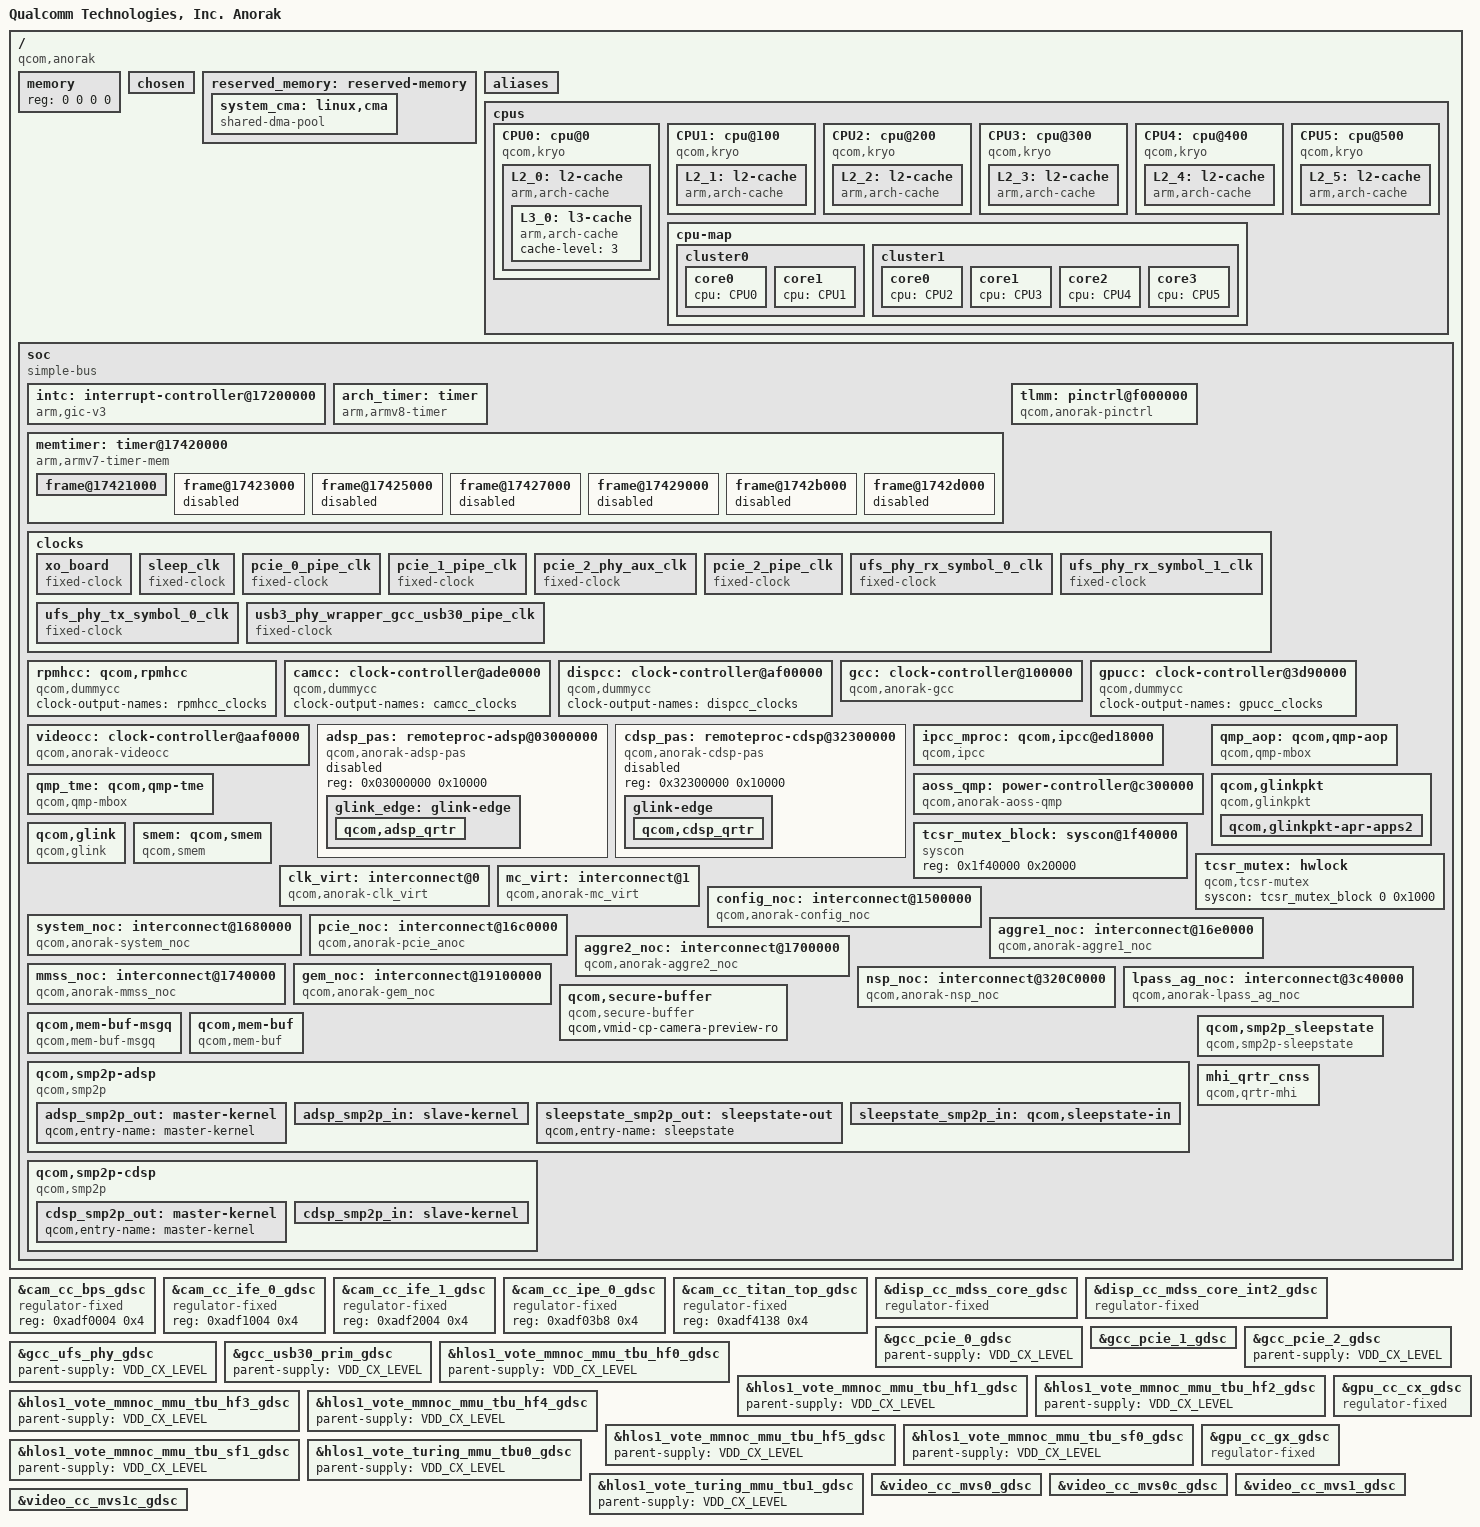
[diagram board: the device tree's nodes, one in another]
#include <dt-bindings/clock/qcom,rpmh.h>
#include <dt-bindings/clock/qcom,camcc-anorak.h>
#include <dt-bindings/clock/qcom,dispcc-anorak.h>
#include <dt-bindings/clock/qcom,gcc-anorak.h>
#include <dt-bindings/clock/qcom,gpucc-anorak.h>
#include <dt-bindings/clock/qcom,videocc-anorak.h>
#include <dt-bindings/interrupt-controller/arm-gic.h>
#include <dt-bindings/interconnect/qcom,icc.h>
#include <dt-bindings/interconnect/qcom,anorak.h>
#include <dt-bindings/soc/qcom,ipcc.h>

/ {
	model = "Qualcomm Technologies, Inc. Anorak";
	compatible = "qcom,anorak";
	qcom,msm-id = <549 0x10000>;
	interrupt-parent = <&intc>;

	#address-cells = <2>;
	#size-cells = <2>;
	memory { device_type = "memory"; reg = <0 0 0 0>; };


	chosen: chosen {
		bootargs = "console=ttyMSM0,115200n8 loglevel=8 log_buf_len=256K kernel.panic_on_rcu_stall=1 loop.max_part=7 service_locator.enable=1 msm_rtb.filter=0x237 allow_mismatched_32bit_el0 kasan=off rcupdate.rcu_expedited=1 rcu_nocbs=0-5 ftrace_dump_on_oops pstore.compress=none kpti=off swiotlb=noforce cgroup.memory=nokmem,nosocket allow_file_spec_access";

	};

	reserved_memory: reserved-memory { };

	aliases { };

	cpus {
		#address-cells = <2>;
		#size-cells = <0>;

		CPU0: cpu@0 {
			device_type = "cpu";
			compatible = "qcom,kryo";
			reg = <0x0 0x0>;
			enable-method = "spin-table";
			cpu-release-addr = <0x0 0x90000000>;
			next-level-cache = <&L2_0>;
			L2_0: l2-cache {
			      compatible = "arm,arch-cache";
			      cache-level = <2>;
			      next-level-cache = <&L3_0>;

				L3_0: l3-cache {
					compatible = "arm,arch-cache";
					cache-level = <3>;
				};
			};
		};

		CPU1: cpu@100 {
			device_type = "cpu";
			compatible = "qcom,kryo";
			reg = <0x0 0x100>;
			enable-method = "spin-table";
			cpu-release-addr = <0x0 0x90000000>;
			next-level-cache = <&L2_1>;
			L2_1: l2-cache {
			      compatible = "arm,arch-cache";
			      cache-level = <2>;
			      next-level-cache = <&L3_0>;
			};

		};

		CPU2: cpu@200 {
			device_type = "cpu";
			compatible = "qcom,kryo";
			reg = <0x0 0x200>;
			enable-method = "spin-table";
			cpu-release-addr = <0x0 0x90000000>;
			next-level-cache = <&L2_2>;
			L2_2: l2-cache {
			      compatible = "arm,arch-cache";
			      cache-level = <2>;
			      next-level-cache = <&L3_0>;
			};
		};

		CPU3: cpu@300 {
			device_type = "cpu";
			compatible = "qcom,kryo";
			reg = <0x0 0x300>;
			enable-method = "spin-table";
			cpu-release-addr = <0x0 0x90000000>;
			next-level-cache = <&L2_3>;
			L2_3: l2-cache {
			      compatible = "arm,arch-cache";
			      cache-level = <2>;
			      next-level-cache = <&L3_0>;
			};

		};

		CPU4: cpu@400 {
			device_type = "cpu";
			compatible = "qcom,kryo";
			reg = <0x0 0x400>;
			enable-method = "spin-table";
			cpu-release-addr = <0x0 0x90000000>;
			next-level-cache = <&L2_4>;
			L2_4: l2-cache {
				compatible = "arm,arch-cache";
				cache-level = <2>;
				next-level-cache = <&L3_0>;
			};
		};

		CPU5: cpu@500 {
			device_type = "cpu";
			compatible = "qcom,kryo";
			reg = <0x0 0x500>;
			enable-method = "spin-table";
			cpu-release-addr = <0x0 0x90000000>;
			next-level-cache = <&L2_5>;
			L2_5: l2-cache {
				compatible = "arm,arch-cache";
				cache-level = <2>;
				next-level-cache = <&L3_0>;
			};
		};

		cpu-map {
			cluster0 {
				core0 {
					cpu = <&CPU0>;
				};

				core1 {
					cpu = <&CPU1>;
				};
			};

			cluster1 {
				core0 {
					cpu = <&CPU2>;
				};

				core1 {
					cpu = <&CPU3>;
				};

				core2 {
					cpu = <&CPU4>;
				};

				core3 {
					cpu = <&CPU5>;
				};
			};
		};
	};

	soc: soc { };
};

#include "anorak-reserved-memory.dtsi"

&reserved_memory {
	#address-cells = <2>;
	#size-cells = <2>;
	ranges;

	/* global autoconfigured region for contiguous allocations */
	system_cma: linux,cma {
		compatible = "shared-dma-pool";
		alloc-ranges = <0x0 0x00000000 0x0 0xffffffff>;
		reusable;
		alignment = <0x0 0x400000>;
		size = <0x0 0x2000000>;
		linux,cma-default;
	};
};

&soc {
	#address-cells = <1>;
	#size-cells = <1>;
	ranges = <0 0 0 0xffffffff>;
	compatible = "simple-bus";

	intc: interrupt-controller@17200000 {
		compatible = "arm,gic-v3";
		#interrupt-cells = <3>;
		interrupt-controller;
		#redistributor-regions = <1>;
		redistributor-stride = <0x0 0x20000>;
		reg = <0x17200000 0x10000>,	/* GICD */
		      <0x17260000 0x100000>;	/* GICR * 8 */
		interrupts = <GIC_PPI 9 IRQ_TYPE_LEVEL_LOW>;
	};

	arch_timer: timer {
		compatible = "arm,armv8-timer";
		interrupts = <GIC_PPI 13 (GIC_CPU_MASK_SIMPLE(8) | IRQ_TYPE_LEVEL_LOW)>,
			     <GIC_PPI 14 (GIC_CPU_MASK_SIMPLE(8) | IRQ_TYPE_LEVEL_LOW)>,
			     <GIC_PPI 11 (GIC_CPU_MASK_SIMPLE(8) | IRQ_TYPE_LEVEL_LOW)>,
			     <GIC_PPI 12 (GIC_CPU_MASK_SIMPLE(8) | IRQ_TYPE_LEVEL_LOW)>;
		clock-frequency = <19200000>;
	};

	memtimer: timer@17420000 {
		#address-cells = <1>;
		#size-cells = <1>;
		ranges;
		compatible = "arm,armv7-timer-mem";
		reg = <0x17420000 0x1000>;
		clock-frequency = <19200000>;

		frame@17421000 {
			frame-number = <0>;
			interrupts = <GIC_SPI 8 IRQ_TYPE_LEVEL_HIGH>,
				     <GIC_SPI 6 IRQ_TYPE_LEVEL_HIGH>;
			reg = <0x17421000 0x1000>,
			      <0x17422000 0x1000>;
		};

		frame@17423000 {
			frame-number = <1>;
			interrupts = <GIC_SPI 9 IRQ_TYPE_LEVEL_HIGH>;
			reg = <0x17423000 0x1000>;
			status = "disabled";
		};

		frame@17425000 {
			frame-number = <2>;
			interrupts = <GIC_SPI 10 IRQ_TYPE_LEVEL_HIGH>;
			reg = <0x17425000 0x1000>;
			status = "disabled";
		};

		frame@17427000 {
			frame-number = <3>;
			interrupts = <GIC_SPI 11 IRQ_TYPE_LEVEL_HIGH>;
			reg = <0x17427000 0x1000>;
			status = "disabled";
		};

		frame@17429000 {
			frame-number = <4>;
			interrupts = <GIC_SPI 12 IRQ_TYPE_LEVEL_HIGH>;
			reg = <0x17429000 0x1000>;
			status = "disabled";
		};

		frame@1742b000 {
			frame-number = <5>;
			interrupts = <GIC_SPI 13 IRQ_TYPE_LEVEL_HIGH>;
			reg = <0x1742b000 0x1000>;
			status = "disabled";
		};

		frame@1742d000 {
			frame-number = <6>;
			interrupts = <GIC_SPI 14 IRQ_TYPE_LEVEL_HIGH>;
			reg = <0x1742d000 0x1000>;
			status = "disabled";
		};
	};

	tlmm: pinctrl@f000000 {
		compatible = "qcom,anorak-pinctrl";
		reg = <0xf000000 0x1000000>;
		interrupts = <GIC_SPI 208 IRQ_TYPE_LEVEL_HIGH>;
		gpio-controller;
		#gpio-cells = <2>;
		interrupt-controller;
		#interrupt-cells = <2>;
	};

	clocks {
		xo_board: xo_board {
			compatible = "fixed-clock";
			clock-frequency = <76800000>;
			clock-output-names = "xo_board";
			#clock-cells = <0>;
		};

		sleep_clk: sleep_clk {
			compatible = "fixed-clock";
			clock-frequency = <32000>;
			clock-output-names = "sleep_clk";
			#clock-cells = <0>;
		};

		pcie_0_pipe_clk: pcie_0_pipe_clk {
			compatible = "fixed-clock";
			clock-frequency = <1000>;
			clock-output-names = "pcie_0_pipe_clk";
			#clock-cells = <0>;
		};

		pcie_1_pipe_clk: pcie_1_pipe_clk {
			compatible = "fixed-clock";
			clock-frequency = <1000>;
			clock-output-names = "pcie_1_pipe_clk";
			#clock-cells = <0>;
		};

		pcie_2_phy_aux_clk: pcie_2_phy_aux_clk {
			compatible = "fixed-clock";
			clock-frequency = <1000>;
			clock-output-names = "pcie_2_phy_aux_clk";
			#clock-cells = <0>;
		};

		pcie_2_pipe_clk: pcie_2_pipe_clk {
			compatible = "fixed-clock";
			clock-frequency = <1000>;
			clock-output-names = "pcie_2_pipe_clk";
			#clock-cells = <0>;
		};

		ufs_phy_rx_symbol_0_clk: ufs_phy_rx_symbol_0_clk {
			compatible = "fixed-clock";
			clock-frequency = <1000>;
			clock-output-names = "ufs_phy_rx_symbol_0_clk";
			#clock-cells = <0>;
		};

		ufs_phy_rx_symbol_1_clk: ufs_phy_rx_symbol_1_clk {
			compatible = "fixed-clock";
			clock-frequency = <1000>;
			clock-output-names = "ufs_phy_rx_symbol_1_clk";
			#clock-cells = <0>;
		};

		ufs_phy_tx_symbol_0_clk: ufs_phy_tx_symbol_0_clk {
			compatible = "fixed-clock";
			clock-frequency = <1000>;
			clock-output-names = "ufs_phy_tx_symbol_0_clk";
			#clock-cells = <0>;
		};

		usb3_phy_wrapper_gcc_usb30_pipe_clk: usb3_phy_wrapper_gcc_usb30_pipe_clk {
			compatible = "fixed-clock";
			clock-frequency = <1000>;
			clock-output-names = "usb3_phy_wrapper_gcc_usb30_pipe_clk";
			#clock-cells = <0>;
		};
	};

	rpmhcc: qcom,rpmhcc {
		compatible = "qcom,dummycc";
		clock-output-names = "rpmhcc_clocks";
		#clock-cells = <1>;
		#reset-cells = <1>;
	};

	camcc: clock-controller@ade0000 {
		compatible = "qcom,dummycc";
		clock-output-names = "camcc_clocks";
		#clock-cells = <1>;
		#reset-cells = <1>;
	};

	dispcc: clock-controller@af00000 {
		compatible = "qcom,dummycc";
		clock-output-names = "dispcc_clocks";
		#clock-cells = <1>;
		#reset-cells = <1>;
	};

	gcc: clock-controller@100000 {
		compatible = "qcom,anorak-gcc", "syscon";
		reg = <0x100000 0x1f4200>;
		reg-name = "cc_base";
		vdd_cx-supply = <&VDD_CX_LEVEL>;
		vdd_mxa-supply = <&VDD_MXA_LEVEL>;
		clocks = <&rpmhcc RPMH_CXO_CLK>, <&sleep_clk>,
			<&pcie_0_pipe_clk>, <&pcie_1_pipe_clk>,
			<&pcie_2_phy_aux_clk>, <&pcie_2_pipe_clk>,
			<&ufs_phy_rx_symbol_0_clk>, <&ufs_phy_rx_symbol_1_clk>,
			<&ufs_phy_tx_symbol_0_clk>, <&usb3_phy_wrapper_gcc_usb30_pipe_clk>;
		clock-names = "bi_tcxo", "sleep_clk",
			"pcie_0_pipe_clk", "pcie_1_pipe_clk",
			"pcie_2_phy_aux_clk", "pcie_2_pipe_clk",
			"ufs_phy_rx_symbol_0_clk", "ufs_phy_rx_symbol_1_clk",
			"ufs_phy_tx_symbol_0_clk", "usb3_phy_wrapper_gcc_usb30_pipe_clk";
		#clock-cells = <1>;
		#reset-cells = <1>;
	};

	gpucc: clock-controller@3d90000 {
		compatible = "qcom,dummycc";
		clock-output-names = "gpucc_clocks";
		#clock-cells = <1>;
		#reset-cells = <1>;
	};

	videocc: clock-controller@aaf0000 {
		compatible = "qcom,anorak-videocc", "syscon";
		reg = <0xaaf0000 0x10000>;
		reg-name = "cc_base";
		vdd_mm-supply = <&VDD_MM_LEVEL>;
		vdd_mxc-supply = <&VDD_MXC_LEVEL>;
		clocks = <&rpmhcc RPMH_CXO_CLK>,
			<&sleep_clk>,
			<&gcc GCC_VIDEO_AHB_CLK>;
		clock-names = "bi_tcxo", "sleep_clk",
			"iface";
		#clock-cells = <1>;
		#reset-cells = <1>;
	};

	adsp_pas: remoteproc-adsp@03000000 {
		compatible = "qcom,anorak-adsp-pas";
		reg = <0x03000000 0x10000>;
		status = "disabled";
		glink_edge: glink-edge {
			qcom,remote-pid = <2>;
			transport = "smem";
			mboxes = <&ipcc_mproc IPCC_CLIENT_LPASS
			IPCC_MPROC_SIGNAL_GLINK_QMP>;
			mbox-names = "adsp_smem";
			interrupt-parent = <&ipcc_mproc>;
			interrupts = <IPCC_CLIENT_LPASS
					IPCC_MPROC_SIGNAL_GLINK_QMP
					IRQ_TYPE_EDGE_RISING>;

			label = "adsp";
			qcom,glink-label = "lpass";

			qcom,adsp_qrtr {
				qcom,glink-channels = "IPCRTR";
				qcom,intents = <0x800  5
						0x2000 3
						0x4400 2>;
			};
		};
	};

	cdsp_pas: remoteproc-cdsp@32300000 {
		compatible = "qcom,anorak-cdsp-pas";
		reg = <0x32300000 0x10000>;
		status = "disabled";
		glink-edge {
			qcom,remote-pid = <5>;
			transport = "smem";
			mboxes = <&ipcc_mproc IPCC_CLIENT_CDSP
					  IPCC_MPROC_SIGNAL_GLINK_QMP>;
			mbox-names = "cdsp_smem";
			interrupt-parent = <&ipcc_mproc>;
			interrupts = <IPCC_CLIENT_CDSP
				  IPCC_MPROC_SIGNAL_GLINK_QMP
				  IRQ_TYPE_EDGE_RISING>;

			label = "cdsp";
			qcom,glink-label = "cdsp";

			qcom,cdsp_qrtr {
				qcom,glink-channels = "IPCRTR";
				qcom,intents = <0x800  5
						0x2000 3
						0x4400 2>;
			};
		};
	};

	ipcc_mproc: qcom,ipcc@ed18000 {
		compatible = "qcom,ipcc";
		reg = <0x408000 0x1000>;
		interrupts = <GIC_SPI 229 IRQ_TYPE_LEVEL_HIGH>;
		interrupt-controller;
		#interrupt-cells = <3>;
		#mbox-cells = <2>;
	};

	aoss_qmp: power-controller@c300000 {
		compatible = "qcom,anorak-aoss-qmp";
		reg = <0xc300000 0x400>;
		interrupt-parent = <&ipcc_mproc>;
		interrupts = <IPCC_CLIENT_AOP
				IPCC_MPROC_SIGNAL_GLINK_QMP
				IRQ_TYPE_EDGE_RISING>;
		mboxes = <&ipcc_mproc IPCC_CLIENT_AOP
		IPCC_MPROC_SIGNAL_GLINK_QMP>;

		#power-domain-cells = <1>;
		#clock-cells = <0>;
	};

	qmp_aop: qcom,qmp-aop {
		compatible = "qcom,qmp-mbox";
		qcom,qmp = <&aoss_qmp>;
		label = "aop";
		#mbox-cells = <1>;
	};

	qmp_tme: qcom,qmp-tme {
		compatible = "qcom,qmp-mbox";
		qcom,remote-pid = <14>;
		mboxes = <&ipcc_mproc IPCC_CLIENT_TME
				IPCC_MPROC_SIGNAL_GLINK_QMP>;
		mbox-names = "tme_qmp";
		interrupt-parent = <&ipcc_mproc>;
		interrupts = <IPCC_CLIENT_TME
				IPCC_MPROC_SIGNAL_GLINK_QMP
				IRQ_TYPE_EDGE_RISING>;

		label = "tme";
		qcom,early-boot;
		priority = <0>;
		mbox-desc-offset = <0x0>;
		#mbox-cells = <1>;
	};

	qcom,glinkpkt {
		compatible = "qcom,glinkpkt";

		qcom,glinkpkt-apr-apps2 {
			qcom,glinkpkt-edge = "adsp";
			qcom,glinkpkt-ch-name = "apr_apps2";
			qcom,glinkpkt-dev-name = "apr_apps2";
		};
	};

	qcom,glink {
		compatible = "qcom,glink";
	};

	tcsr_mutex_block: syscon@1f40000 {
		compatible = "syscon";
		reg = <0x1f40000 0x20000>;
	};

	tcsr_mutex: hwlock {
		compatible = "qcom,tcsr-mutex";
		syscon = <&tcsr_mutex_block 0 0x1000>;
		#hwlock-cells = <1>;
		};

	smem: qcom,smem {
		compatible = "qcom,smem";
		memory-region = <&smem_mem>;
		hwlocks = <&tcsr_mutex 3>;
	};

	clk_virt: interconnect@0 {
		compatible = "qcom,anorak-clk_virt";
		#interconnect-cells = <1>;
	};

	mc_virt: interconnect@1 {
		compatible = "qcom,anorak-mc_virt";
		#interconnect-cells = <1>;
	};

	config_noc: interconnect@1500000 {
		compatible = "qcom,anorak-config_noc";
		#interconnect-cells = <1>;
	};

	system_noc: interconnect@1680000 {
		compatible = "qcom,anorak-system_noc";
		#interconnect-cells = <1>;
	};

	pcie_noc: interconnect@16c0000 {
		compatible = "qcom,anorak-pcie_anoc";
		#interconnect-cells = <1>;
	};

	aggre1_noc: interconnect@16e0000 {
		compatible = "qcom,anorak-aggre1_noc";
		#interconnect-cells = <1>;
	};

	aggre2_noc: interconnect@1700000 {
		compatible = "qcom,anorak-aggre2_noc";
		#interconnect-cells = <1>;
	};

	mmss_noc: interconnect@1740000 {
		compatible = "qcom,anorak-mmss_noc";
		#interconnect-cells = <1>;
	};

	gem_noc: interconnect@19100000 {
		compatible = "qcom,anorak-gem_noc";
		#interconnect-cells = <1>;
	};

	nsp_noc: interconnect@320C0000 {
		compatible = "qcom,anorak-nsp_noc";
		#interconnect-cells = <1>;
	};

	lpass_ag_noc: interconnect@3c40000 {
		compatible = "qcom,anorak-lpass_ag_noc";
		#interconnect-cells = <1>;
	};

	qcom,secure-buffer {
		compatible = "qcom,secure-buffer";
		qcom,vmid-cp-camera-preview-ro;
	};

	qcom,mem-buf-msgq {
		compatible = "qcom,mem-buf-msgq";
	};

	qcom,mem-buf {
		compatible = "qcom,mem-buf";
		qcom,mem-buf-capabilities = "supplier";
		qcom,vmid = <3>;
	};

	qcom,smp2p-adsp {
		compatible = "qcom,smp2p";
		qcom,smem = <443>, <429>;
		interrupt-parent = <&ipcc_mproc>;
		interrupts = <IPCC_CLIENT_LPASS IPCC_MPROC_SIGNAL_SMP2P
			      IRQ_TYPE_EDGE_RISING>;
		mboxes = <&ipcc_mproc IPCC_CLIENT_LPASS
			  IPCC_MPROC_SIGNAL_SMP2P>;
		qcom,local-pid = <0>;
		qcom,remote-pid = <2>;

		adsp_smp2p_out: master-kernel {
			qcom,entry-name = "master-kernel";
			#qcom,smem-state-cells = <1>;
		};

		adsp_smp2p_in: slave-kernel {
			qcom,entry-name = "slave-kernel";
			interrupt-controller;
			#interrupt-cells = <2>;
		};

		sleepstate_smp2p_out: sleepstate-out {
			qcom,entry-name = "sleepstate";
			#qcom,smem-state-cells = <1>;
		};

		sleepstate_smp2p_in: qcom,sleepstate-in {
			qcom,entry-name = "sleepstate_see";
			interrupt-controller;
			#interrupt-cells = <2>;
		};
	};

	qcom,smp2p-cdsp {
		compatible = "qcom,smp2p";
		qcom,smem = <94>, <432>;
		interrupt-parent = <&ipcc_mproc>;
		interrupts = <IPCC_CLIENT_CDSP IPCC_MPROC_SIGNAL_SMP2P
			      IRQ_TYPE_EDGE_RISING>;
		mboxes = <&ipcc_mproc IPCC_CLIENT_CDSP IPCC_MPROC_SIGNAL_SMP2P>;
		qcom,local-pid = <0>;
		qcom,remote-pid = <5>;

		cdsp_smp2p_out: master-kernel {
			qcom,entry-name = "master-kernel";
			#qcom,smem-state-cells = <1>;
		};

		cdsp_smp2p_in: slave-kernel {
			qcom,entry-name = "slave-kernel";
			interrupt-controller;
			#interrupt-cells = <2>;
		};
	};

	qcom,smp2p_sleepstate {
		compatible = "qcom,smp2p-sleepstate";
		qcom,smem-states = <&sleepstate_smp2p_out 0>;
		interrupt-parent = <&sleepstate_smp2p_in>;
		interrupts = <0 0>;
		interrupt-names = "smp2p-sleepstate-in";
	};

	mhi_qrtr_cnss {
		compatible = "qcom,qrtr-mhi";
		qcom,dev-id = <0x1103>;
		qcom,net-id = <0>;
		qcom,low-latency;
	};
};

#include "diwali-gdsc.dtsi"

&cam_cc_bps_gdsc {
	compatible = "regulator-fixed";
	reg = <0xadf0004 0x4>;
	status = "ok";
};

&cam_cc_ife_0_gdsc {
	compatible = "regulator-fixed";
	reg = <0xadf1004 0x4>;
	status = "ok";
};

&cam_cc_ife_1_gdsc {
	compatible = "regulator-fixed";
	reg = <0xadf2004 0x4>;
	status = "ok";
};

&cam_cc_ipe_0_gdsc {
	compatible = "regulator-fixed";
	reg = <0xadf03b8 0x4>;
	status = "ok";
};

&cam_cc_titan_top_gdsc {
	compatible = "regulator-fixed";
	reg = <0xadf4138 0x4>;
	status = "ok";
};

&disp_cc_mdss_core_gdsc {
	compatible = "regulator-fixed";
	status = "ok";
};

&disp_cc_mdss_core_int2_gdsc {
	compatible = "regulator-fixed";
	status = "ok";
};

&gcc_pcie_0_gdsc {
	parent-supply = <&VDD_CX_LEVEL>;
	status="ok";
};

&gcc_pcie_1_gdsc {
	parent-supply = <&VDD_CX_LEVEL>;
	reg = <0x1ad004 0x4>;
	qcom,support-hw-trigger;
	status="ok";
};

&gcc_pcie_2_gdsc {
	parent-supply = <&VDD_CX_LEVEL>;
	status="ok";
};

&gcc_ufs_phy_gdsc {
	parent-supply = <&VDD_CX_LEVEL>;
	status = "ok";
};

&gcc_usb30_prim_gdsc {
	parent-supply = <&VDD_CX_LEVEL>;
	status = "ok";
};

&hlos1_vote_mmnoc_mmu_tbu_hf0_gdsc {
	parent-supply = <&VDD_CX_LEVEL>;
	status = "ok";
};

&hlos1_vote_mmnoc_mmu_tbu_hf1_gdsc {
	parent-supply = <&VDD_CX_LEVEL>;
	status = "ok";
};

&hlos1_vote_mmnoc_mmu_tbu_hf2_gdsc {
	parent-supply = <&VDD_CX_LEVEL>;
	status = "ok";
};

&hlos1_vote_mmnoc_mmu_tbu_hf3_gdsc {
	parent-supply = <&VDD_CX_LEVEL>;
	status = "ok";
};

&hlos1_vote_mmnoc_mmu_tbu_hf4_gdsc {
	parent-supply = <&VDD_CX_LEVEL>;
	status = "ok";
};

&hlos1_vote_mmnoc_mmu_tbu_hf5_gdsc {
	parent-supply = <&VDD_CX_LEVEL>;
	status = "ok";
};

&hlos1_vote_mmnoc_mmu_tbu_sf0_gdsc {
	parent-supply = <&VDD_CX_LEVEL>;
	status = "ok";
};

&hlos1_vote_mmnoc_mmu_tbu_sf1_gdsc {
	parent-supply = <&VDD_CX_LEVEL>;
	status = "ok";
};

&hlos1_vote_turing_mmu_tbu0_gdsc {
	parent-supply = <&VDD_CX_LEVEL>;
	status = "ok";
};

&hlos1_vote_turing_mmu_tbu1_gdsc {
	parent-supply = <&VDD_CX_LEVEL>;
	status = "ok";
};

&gpu_cc_cx_gdsc {
	compatible = "regulator-fixed";
	status = "ok";
};

&gpu_cc_gx_gdsc {
	compatible = "regulator-fixed";
	status = "ok";
};

&video_cc_mvs0_gdsc {
	reg = <0xaaf809c 0x4>;
	clocks = <&gcc GCC_VIDEO_AHB_CLK>;
	clock-names = "ahb_clk";
	parent-supply = <&VDD_MM_MXC_VOTER_LEVEL>;
	status = "ok";
};

&video_cc_mvs0c_gdsc {
	reg = <0xaaf804c 0x4>;
	clocks = <&gcc GCC_VIDEO_AHB_CLK>;
	clock-names = "ahb_clk";
	parent-supply = <&VDD_MM_MXC_VOTER_LEVEL>;
	status = "ok";
};

&video_cc_mvs1_gdsc {
	reg = <0xaaf80c0 0x4>;
	clocks = <&gcc GCC_VIDEO_AHB_CLK>;
	clock-names = "ahb_clk";
	parent-supply = <&VDD_MM_MXC_VOTER_LEVEL>;
	status = "ok";
};

&video_cc_mvs1c_gdsc {
	reg = <0xaaf8074 0x4>;
	clocks = <&gcc GCC_VIDEO_AHB_CLK>;
	clock-names = "ahb_clk";
	parent-supply = <&VDD_MM_MXC_VOTER_LEVEL>;
	status = "ok";

};

#include "anorak-usb.dtsi"
#include "anorak-pinctrl.dtsi"
#include "anorak-stub-regulator.dtsi"
#include "anorak-dma-heaps.dtsi"
#include "ipcc-test.dtsi"
